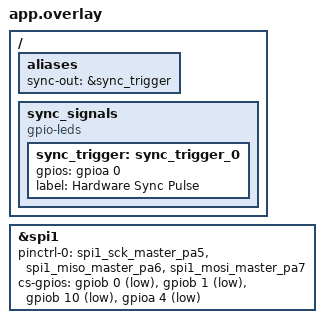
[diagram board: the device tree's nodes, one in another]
/ {
    aliases {
        sync-out = &sync_trigger;
    };

    /* Use a dedicated node for the sync signal */
    sync_signals {
        compatible = "gpio-leds";
        sync_trigger: sync_trigger_0 {
            /* Adjust PA0 to your preferred physical pin */
            gpios = <&gpioa 0 GPIO_ACTIVE_HIGH>;
            label = "Hardware Sync Pulse";
        };
    };
};
&spi1 {
    status = "okay";
    pinctrl-0 = <&spi1_sck_master_pa5 &spi1_miso_master_pa6 &spi1_mosi_master_pa7>;
    pinctrl-names = "default";
    
    cs-gpios = <&gpiob 0 GPIO_ACTIVE_LOW>,   /* Slave 0 */
               <&gpiob 1 GPIO_ACTIVE_LOW>,   /* Slave 1 */
               <&gpiob 10 GPIO_ACTIVE_LOW>,  /* Slave 2 */
               <&gpioa 4 GPIO_ACTIVE_LOW>;   /* Slave 3 */
};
